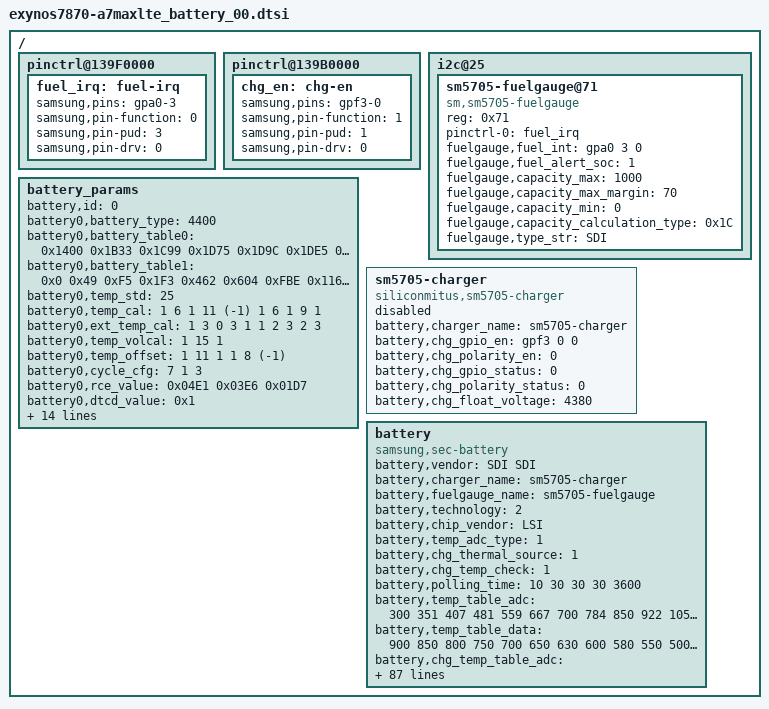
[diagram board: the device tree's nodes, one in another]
/*
 * SAMSUNG UNIVERSAL5433 board device tree source
 *
 * Copyright (c) 2013 Samsung Electronics Co., Ltd.
 *		http://www.samsung.com
 *
 * This program is free software; you can redistribute it and/or modify
 * it under the terms of the GNU General Public License version 2 as
 * published by the Free Software Foundation.
*/

/ {
	pinctrl@139F0000 {
		fuel_irq: fuel-irq {
			samsung,pins = "gpa0-3";
			samsung,pin-function = <0>;
			samsung,pin-pud = <3>;
			samsung,pin-drv = <0>;
		};
	};

	pinctrl@139B0000 {
		chg_en: chg-en {
			samsung,pins = "gpf3-0";
			samsung,pin-function = <1>;
			samsung,pin-pud = <1>;
			samsung,pin-drv = <0>;
		};
	};

	i2c@25 {
		sm5705-fuelgauge@71 {
			compatible = "sm,sm5705-fuelgauge";
			reg = <0x71>;
			pinctrl-names = "default";
			pinctrl-0 = <&fuel_irq>;
			fuelgauge,fuel_int = <&gpa0 3 0>;
			fuelgauge,fuel_alert_soc = <1>;
			fuelgauge,capacity_max = <1000>;
			fuelgauge,capacity_max_margin = <70>;
			fuelgauge,capacity_min = <0>;
			fuelgauge,capacity_calculation_type = <0x1C>;
			fuelgauge,type_str = "SDI";
		};
	};

	battery_params {
		battery,id = <0>; /* -1 means auto, detected by F/G */
		battery0,battery_type = <4400>; /* 4200 4350 4400 */
		battery0,battery_table0 = <0x1400 0x1B33 0x1C99 0x1D75 0x1D9C 0x1DE5 0x1EBB 0x1EF5 0x1F93 0x1FF9 0x2032 0x207E 0x20D2 0x2222 0x22A3 0x2399>;
		battery0,battery_table1 = <0x0 0x49 0xF5 0x1F3 0x462 0x604 0xFBE 0x1160 0x13CE 0x163D 0x1712 0x17DF 0x1981 0x1E5E 0x2000 0x2018>;
		battery0,temp_std = <25>;
		battery0,temp_cal = <1 6 1 11 (-1) 1 6 1 9 1>; /* en_h, p_de, p_fa, n_de, n_fa, en_l, p_de, p_fa, n_de, n_fa, */
		battery0,ext_temp_cal = <1 3 0 3 1 1 2 3 2 3>; /* en_h, p_de, p_fa, n_de, n_fa, en_l, p_de, p_fa, n_de, n_fa, */
		battery0,temp_volcal = <1 15 1>; /* en, temp, cal */
		battery0,temp_offset = <1 11 1 1 8 (-1)>; /* en_high level offset en_low level offset */
		battery0,cycle_cfg = <7 1 3>; /*high_limit low_limit cntl*/
		battery0,rce_value = <0x04E1 0x03E6 0x01D7>;
		battery0,dtcd_value = <0x1>;
		battery0,rs_value = <0x0051 0x147 0x47a 0x3800 0x00a4>; /*rs p_mix_factor n_mix_factor max min*/
		battery0,vit_period = <0x3506>;
		battery0,mix_value = <0x0503 0x0004>; /*mix_rate init_blank*/
		battery0,misc = <0x0060>;
		battery0,topoff_soc = <0 3 350>; /*enable soc current*/
		battery0,curr_offset = <1 0x0000>; /*en_auto offset*/
		battery0,volt_cal = <0x8000>;
		battery0,p_curr_cal = <0x0094>;
		battery0,n_curr_cal = <0x0092>;
		battery0,curr_lcal = <0 0x8888 0x8888 0x8888>;
		battery0,tem_poff = <3350 50 3200 50>;
		battery0,v_offset_cancel = <1 0 100 10>; /* en_p, en_n, level, mohm */
		battery0,v_alarm = <3000>;
	};

	sm5705-charger {
		status = "disable";
		compatible = "siliconmitus,sm5705-charger";

		/* Charger */
		battery,charger_name = "sm5705-charger";
		battery,chg_gpio_en = <&gpf3 0 0>;
		battery,chg_polarity_en = <0>;
		battery,chg_gpio_status = <0>;
		battery,chg_polarity_status = <0>;
		battery,chg_float_voltage = <4380>;
	};

	battery {
		status = "okay";

		compatible = "samsung,sec-battery";
		battery,vendor = "SDI SDI";
		battery,charger_name = "sm5705-charger";
		battery,fuelgauge_name = "sm5705-fuelgauge";
		battery,technology = <2>; /* POWER_SUPPLY_TECHNOLOGY_LION */

		battery,chip_vendor = "LSI";
		battery,temp_adc_type = <1>; /* SEC_BATTERY_ADC_TYPE_AP */

		battery,chg_thermal_source = <1>;
		battery,chg_temp_check = <1>;

		battery,polling_time = <10 30 30 30 3600>;

		battery,temp_table_adc = <300 351 407 481 559 667 700 784 850 922 1056 1189 1404 1602 2026 2245 2460 2874 2932 3180 3229 3305 3335 3410>;
		battery,temp_table_data = <900 850 800 750 700 650 630 600 580 550 500 460 400 350 250 200 150 50 0 (-50) (-70) (-100) (-150) (-200)>;

		battery,chg_temp_table_adc = <300 351 407 481 559 667 700 784 850 922 1056 1189 1404 1602 2026 2245 2460 2874 2932 3180 3229 3305 3335 3410>;
		battery,chg_temp_table_data = <900 850 800 750 700 650 630 600 580 550 500 460 400 350 250 200 150 50 0 (-50) (-70) (-100) (-150) (-200)>;

		battery,input_current_limit = <1800 475 475 1800 475 900 1000 475 1000 0 820 820 820 1900 1800 0 0 400 700 1300 300 1000 1500 0 1650 1650 1000 1650 80 1800 1650 1400 1000 1000 820 820>;
		battery,fast_charging_current = <2100 0 0 2100 500 1200 1000 500 1200 0 1200 1200 1200 1600 2100 0 0 400 700 1300 300 1000 1500 0 3000 3000 1000 3000 80 1800 1000 1400 0 1000 1200 1200>;
		battery,full_check_current_1st = <350 0 0 350 350 350 350 350 350 0 350 350 350 350 350 0 0 350 350 350 350 350 350 0 350 350 350 350 0 350 350 350 0 350 350 350>;
		battery,full_check_current_2nd = <125 0 0 125 125 125 125 125 125 0 125 125 125 125 125 0 0 125 125 125 125 125 125 0 125 125 125 125 0 125 100 125 0 125 125 125>;

		battery,inbat_voltage = <1>;
		battery,inbat_voltage_table_adc = <2739 2722 2697 2678 2643 2628 2599 2573 2547 2521 2495 2474 2440 2423 2393 2359 2347 2317 2291 2267 2240>;
		battery,inbat_voltage_table_data = <438 435 430 426 419 416 410 405 400 395 390 385 380 375 370 365 360 355 350 345 340>;

		battery,adc_check_count = <5>;

		battery,cable_check_type = <4>; /* SEC_BATTERY_CABLE_CHECK_PSY */
		battery,cable_source_type = <1>; /* SEC_BATTERY_CABLE_SOURCE_EXTERNAL */
		battery,polling_type = <1>; /* SEC_BATTERY_MONITOR_ALARM */
		battery,monitor_initial_count = <0>;

		battery,battery_check_type = <0>; /* SEC_BATTERY_CHECK_NONE */
		battery,check_count = <0>;
		battery,check_adc_max = <1440>;
		battery,check_adc_min = <0>;

		battery,ovp_uvlo_check_type = <3>; /* SEC_BATTERY_OVP_UVLO_CHGPOLLING */

		battery,thermal_source = <2>; /* SEC_BATTERY_THERMAL_SOURCE_ADC */

		battery,temp_check_type = <2>; /* SEC_BATTERY_TEMP_CHECK_TEMP */
		battery,temp_check_count = <1>;
		battery,temp_highlimit_threshold_normal = <800>;
		battery,temp_highlimit_recovery_normal = <750>;
		battery,temp_high_threshold_normal = <550>;
		battery,temp_high_recovery_normal = <500>;
		battery,temp_low_threshold_normal = <(-50)>;
		battery,temp_low_recovery_normal = <0>;
		battery,temp_highlimit_threshold_lpm = <800>;
		battery,temp_highlimit_recovery_lpm = <750>;
		battery,temp_high_threshold_lpm = <550>;
		battery,temp_high_recovery_lpm = <500>;
		battery,temp_low_threshold_lpm = <(-50)>;
		battery,temp_low_recovery_lpm = <0>;

		battery,full_check_type = <2>; /* SEC_BATTERY_FULLCHARGED_FG_CURRENT */
		battery,full_check_type_2nd = <2>; /* SEC_BATTERY_FULLCHARGED_FG_CURRENT */
		battery,full_check_count = <1>;
		battery,chg_gpio_full_check = <0>;
		battery,chg_polarity_full_check = <1>;

		battery,chg_high_temp_1st = <465>;
		battery,chg_high_temp_2nd = <465>;
		battery,chg_high_temp_recovery = <455>;
		battery,chg_charging_limit_current = <1400>;
		battery,chg_charging_limit_current_2nd = <1400>;
		battery,chg_skip_check_capacity = <10>;
		battery,chg_skip_check_time = <600>;

		/* SEC_BATTERY_FULL_CONDITION_SOC |
		   SEC_BATTERY_FULL_CONDITION_NOTIMEFULL |
		   SEC_BATTERY_FULL_CONDITION_VCELL */
		battery,full_condition_type = <13>;
		battery,full_condition_soc = <93>;
		battery,full_condition_vcell = <4280>;

		battery,recharge_check_count = <2>;
		battery,recharge_condition_type = <4>; /* SEC_BATTERY_RECHARGE_CONDITION_VCELL */
		battery,recharge_condition_soc = <98>;
		battery,recharge_condition_vcell = <4330>;

		battery,charging_total_time = <21600>;
		battery,recharging_total_time = <5400>;
		battery,charging_reset_time = <0>;

		battery,chg_float_voltage = <4380>;

		battery,self_discharging_temp_block = <600>;
		battery,self_discharging_volt_block = <4250>;
		battery,self_discharging_temp_recov = <550>;
		battery,self_discharging_temp_pollingtime = <400>;

		battery,swelling_high_temp_block = <450>;
		battery,swelling_high_temp_recov = <400>;
		battery,swelling_low_temp_block = <100>;
		battery,swelling_low_temp_recov = <150>;

		battery,swelling_low_temp_current = <1650>;	/* 0.5C */
		battery,swelling_low_temp_topoff = <200>;	/* 0.05C */
		battery,swelling_high_temp_current = <2300>;	/* 0.7C */
		battery,swelling_high_temp_topoff = <200>;	/* 0.05C */

		battery,swelling_drop_float_voltage = <4200>;
		battery,swelling_high_rechg_voltage = <4150>;
		battery,swelling_low_rechg_voltage = <4050>;

		battery,siop_input_limit_current = <1200>;
		battery,siop_charging_limit_current = <1000>;
		battery,siop_hv_input_limit_current = <700>;
		battery,siop_hv_charging_limit_current = <1000>;

		battery,store_mode_afc_input_current = <450>;

		io-channels = <&exynos_adc 1>, <&exynos_adc 3>, <&exynos_adc 6>;
		io-channel-names = "adc-temp", "adc-chg-temp", "adc-in-bat";
		#io-channel-cells = <3>;
		io-channel-ranges;
	};
};
